VERSION "HNNBNNNYNNNNNNNNNNNNNNNNNNNNNNNNNNNNNNNNNN/4/%%%/4/'%**4NNN///"

NS_ :

BS_:

BU_: LLP_L LLP_R AFS

BO_ 3221225472 VECTOR__INDEPENDENT_SIG_MSG: 0 Vector__XXX
 SG_ New_Signal_167_Copy_17 : 0|1@1+ (1,0) [0|0] "" Vector__XXX
 SG_ New_Signal_167_Copy_16 : 0|1@1+ (1,0) [0|0] "" Vector__XXX
 SG_ New_Signal_167_Copy_15 : 0|1@1+ (1,0) [0|0] "" Vector__XXX
 SG_ New_Signal_167_Copy_14 : 0|1@1+ (1,0) [0|0] "" Vector__XXX
 SG_ SOA_Variante_2 : 0|8@1+ (1,0) [0|255] "" Vector__XXX
 SG_ SOA_Variante : 0|8@1+ (1,0) [0|255] "" Vector__XXX
 SG_ SOA_DimAbLicht_R : 0|8@1+ (0.4,0) [0|100] "Unit_PerCent" Vector__XXX
 SG_ SOA_StGlDim_R : 0|1@1+ (1,0) [0|1] "" Vector__XXX
 SG_ SOA_StGlTest_R : 0|1@1+ (1,0) [0|1] "" Vector__XXX
 SG_ SOA_RefLauf_R : 0|1@1+ (1,0) [0|1] "" Vector__XXX
 SG_ SOA_FehlPos_R : 0|1@1+ (1,0) [0|1] "" Vector__XXX
 SG_ SOA_SollPos_R : 0|12@1+ (0.015625,-31.96875) [-31.96875|31.953125] "Unit_DegreOfArc" Vector__XXX
 SG_ SOA_DimAbLicht_L : 0|8@1+ (0.4,0) [0|100] "Unit_PerCent" Vector__XXX
 SG_ SOA_StGlDim_L : 0|1@1+ (1,0) [0|1] "" Vector__XXX
 SG_ SOA_StGlTest_L : 0|1@1+ (1,0) [0|1] "" Vector__XXX
 SG_ SOA_RefLauf_L : 0|1@1+ (1,0) [0|1] "" Vector__XXX
 SG_ SOA_FehlPos_L : 0|1@1+ (1,0) [0|1] "" Vector__XXX
 SG_ SOA_SollPos_L : 0|12@1+ (0.015625,-31.96875) [-31.96875|31.953125] "Unit_DegreOfArc" Vector__XXX
 SG_ BM_ZV_zu : 0|1@1+ (1,0) [0|1] "" Vector__XXX
 SG_ BM_ZV_auf : 0|1@1+ (1,0) [0|1] "" Vector__XXX
 SG_ BM_Autobahn : 0|1@1+ (1,0) [0|1] "" Vector__XXX
 SG_ LCM_ECE_SAE_Umschaltung_Anf : 0|1@1+ (1,0) [0|1] "" Vector__XXX
 SG_ LCM_Signaturlicht_Anf : 0|1@1+ (1,0) [0|1] "" Vector__XXX
 SG_ LCM_Animiertes_TFL_Anf : 0|3@1+ (1,0) [0|7] "" Vector__XXX
 SG_ LCM_Blinkerwischen_Anf : 0|1@1+ (1,0) [0|1] "" Vector__XXX
 SG_ LCM_Leistungsreduzierung_Anf : 0|2@1+ (1,0) [0|3] "" Vector__XXX
 SG_ LCM_PL_R_Anf : 0|1@1+ (1,0) [0|1] "" Vector__XXX
 SG_ LCM_PL_L_Anf : 0|1@1+ (1,0) [0|1] "" Vector__XXX
 SG_ LCM_PO_R_Anf : 0|1@1+ (1,0) [0|1] "" Vector__XXX
 SG_ LCM_PO_L_Anf : 0|1@1+ (1,0) [0|1] "" Vector__XXX
 SG_ LCM_univ_1_R_Anf : 0|1@1+ (1,0) [0|1] "" Vector__XXX
 SG_ LCM_univ_1_L_Anf : 0|1@1+ (1,0) [0|1] "" Vector__XXX
 SG_ LCM_SM_R_Anf : 0|1@1+ (1,0) [0|1] "" Vector__XXX
 SG_ LCM_SM_L_Anf : 0|1@1+ (1,0) [0|1] "" Vector__XXX
 SG_ LCM_Sh_R_Anf : 0|1@1+ (1,0) [0|1] "" Vector__XXX
 SG_ LCM_Sh_L_Anf : 0|1@1+ (1,0) [0|1] "" Vector__XXX
 SG_ LCM_Blinkerzyklus_R : 0|1@1+ (1,0) [0|1] "" Vector__XXX
 SG_ LCM_Blinkerzyklus_L : 0|1@1+ (1,0) [0|1] "" Vector__XXX
 SG_ LCM_Blinker_R_Anf : 0|1@1+ (1,0) [0|1] "" Vector__XXX
 SG_ LCM_Blinker_L_Anf : 0|1@1+ (1,0) [0|1] "" Vector__XXX
 SG_ LCM_Abschaltung_Vbat_R_Anf : 0|1@1+ (1,0) [0|1] "" Vector__XXX
 SG_ LCM_Abschaltung_Vbat_L_Anf : 0|1@1+ (1,0) [0|1] "" Vector__XXX
 SG_ LCM_TFL_R_Anf : 0|1@1+ (1,0) [0|1] "" Vector__XXX
 SG_ LCM_TFL_L_Anf : 0|1@1+ (1,0) [0|1] "" Vector__XXX
 SG_ LCM_Soll_BZ : 0|4@1+ (1,0) [0|15] "" Vector__XXX
 SG_ LCM_Soll_CRC : 0|8@1+ (1,0) [0|255] "" Vector__XXX
 SG_ LED_L_Abblendl_Anf : 0|1@1+ (1,0) [0|1] "" Vector__XXX
 SG_ LED_L_Abblendl_Schaltart : 0|1@1+ (1,0) [0|1] "" Vector__XXX
 SG_ LED_R_Abblendl_Anf : 0|1@1+ (1,0) [0|1] "" Vector__XXX
 SG_ LED_R_Abblendl_Schaltart : 0|1@1+ (1,0) [0|1] "" Vector__XXX
 SG_ LED_L_Fernl_LH_Anf : 0|1@1+ (1,0) [0|1] "" Vector__XXX
 SG_ LED_L_Fernl_LH_Schaltart : 0|1@1+ (1,0) [0|1] "" Vector__XXX
 SG_ LED_R_Fernl_LH_Anf : 0|1@1+ (1,0) [0|1] "" Vector__XXX
 SG_ LED_R_Fernl_LH_Schaltart : 0|1@1+ (1,0) [0|1] "" Vector__XXX
 SG_ LED_L_Nebel_All_Anf : 0|1@1+ (1,0) [0|1] "" Vector__XXX
 SG_ LED_L_Nebel_All_Schaltart : 0|1@1+ (1,0) [0|1] "" Vector__XXX
 SG_ LED_R_Nebel_All_Anf : 0|1@1+ (1,0) [0|1] "" Vector__XXX
 SG_ LED_R_Nebel_All_Schaltart : 0|1@1+ (1,0) [0|1] "" Vector__XXX
 SG_ LED_Sta_Diag : 0|4@1+ (1,0) [0|15] "" Vector__XXX
 SG_ LED_L_Zus_Fernl_LH_Anf : 0|1@1+ (1,0) [0|1] "" Vector__XXX
 SG_ LED_L_Zus_Fernl_LH_Schaltart : 0|1@1+ (1,0) [0|1] "" Vector__XXX
 SG_ LED_R_Zus_Fernl_LH_Anf : 0|1@1+ (1,0) [0|1] "" Vector__XXX
 SG_ LED_R_Zus_Fernl_LH_Schaltart : 0|1@1+ (1,0) [0|1] "" Vector__XXX
 SG_ SOL_SollPos_L : 0|12@1+ (0.5,-1023) [-1023|1022.5] "Unit_MilliMeter" Vector__XXX
 SG_ SOL_FehlPos_L : 0|1@1+ (1,0) [0|1] "" Vector__XXX
 SG_ SOL_RefLauf_L : 0|1@1+ (1,0) [0|1] "" Vector__XXX
 SG_ SOL_StGlTest_L : 0|1@1+ (1,0) [0|1] "" Vector__XXX
 SG_ SOL_Fehlloesch_L : 0|1@1+ (1,0) [0|1] "" Vector__XXX
 SG_ MO_StartStopp_Motorstopp : 0|1@1+ (1,0) [0|1] "" Vector__XXX
 SG_ MO_StartStopp_Wiederstart : 0|1@1+ (1,0) [0|1] "" Vector__XXX
 SG_ SOL_Tieftemp_Flag : 0|1@1+ (1,0) [0|1] "" Vector__XXX
 SG_ SOL_SollPos_R : 0|12@1+ (0.5,-1023) [-1023|1022.5] "Unit_MilliMeter" Vector__XXX
 SG_ SOL_FehlPos_R : 0|1@1+ (1,0) [0|1] "" Vector__XXX
 SG_ SOL_RefLauf_R : 0|1@1+ (1,0) [0|1] "" Vector__XXX
 SG_ SOL_StGlTest_R : 0|1@1+ (1,0) [0|1] "" Vector__XXX
 SG_ SOL_Fehlloesch_R : 0|1@1+ (1,0) [0|1] "" Vector__XXX
 SG_ SOL_Sta_Diag : 0|4@1+ (1,0) [0|15] "" Vector__XXX
 SG_ MXB_LED_37 : 0|6@1- (1,0) [0|0] "" Vector__XXX
 SG_ MXB_LED_36 : 0|6@1- (1,0) [0|0] "" Vector__XXX
 SG_ MXB_LED_35 : 0|6@1- (1,0) [0|0] "" Vector__XXX
 SG_ MXB_LED_34 : 0|6@1- (1,0) [0|0] "" Vector__XXX
 SG_ MXB_LED_33 : 0|6@1- (1,0) [0|0] "" Vector__XXX
 SG_ MXB_LED_32 : 0|6@1+ (1,0) [0|0] "" Vector__XXX
 SG_ MXB_LED_31 : 0|6@1+ (1,0) [0|0] "" Vector__XXX
 SG_ MXB_LED_30 : 0|6@1+ (1,0) [0|0] "" Vector__XXX
 SG_ MXB_LED_29 : 0|6@1+ (1,0) [0|0] "" Vector__XXX
 SG_ MXB_LED_28 : 0|6@1+ (1,0) [0|0] "" Vector__XXX
 SG_ MXB_LED_27 : 0|6@1+ (1,0) [0|0] "" Vector__XXX
 SG_ MXB_LED_26 : 0|6@1+ (1,0) [0|0] "" Vector__XXX
 SG_ MXB_LED_25 : 0|6@1+ (1,0) [0|0] "" Vector__XXX
 SG_ MXB_LED_24 : 0|6@1+ (1,0) [0|0] "" Vector__XXX
 SG_ MXB_LED_23 : 0|6@1+ (1,0) [0|0] "" Vector__XXX
 SG_ MXB_LED_22 : 0|6@1+ (1,0) [0|0] "" Vector__XXX
 SG_ MXB_LED_21 : 0|6@1+ (1,0) [0|0] "" Vector__XXX
 SG_ MXB_LED_20 : 0|6@1+ (1,0) [0|0] "" Vector__XXX
 SG_ MXB_LED_19 : 0|6@1+ (1,0) [0|0] "" Vector__XXX
 SG_ MXB_LED_18 : 0|6@1+ (1,0) [0|0] "" Vector__XXX
 SG_ MXB_LED_17 : 0|6@1+ (1,0) [0|0] "" Vector__XXX
 SG_ MXB_LED_16 : 0|6@1+ (1,0) [0|0] "" Vector__XXX
 SG_ MXB_LED_15 : 0|6@1+ (1,0) [0|0] "" Vector__XXX
 SG_ MXB_LED_14 : 0|6@1+ (1,0) [0|0] "" Vector__XXX
 SG_ MXB_LED_13 : 0|6@1+ (1,0) [0|0] "" Vector__XXX
 SG_ MXB_LED_12 : 0|6@1+ (1,0) [0|0] "" Vector__XXX
 SG_ MXB_LED_11 : 0|6@1+ (1,0) [0|0] "" Vector__XXX
 SG_ MXB_LED_10 : 0|6@1+ (1,0) [0|0] "" Vector__XXX
 SG_ MXB_LED_09 : 0|6@1+ (1,0) [0|0] "" Vector__XXX
 SG_ MXB_LED_08 : 0|6@1+ (1,0) [0|0] "" Vector__XXX
 SG_ MXB_LED_07 : 0|6@1+ (1,0) [0|0] "" Vector__XXX
 SG_ MXB_LED_06 : 0|6@1+ (1,0) [0|0] "" Vector__XXX
 SG_ MXB_LED_05 : 0|6@1+ (1,0) [0|0] "" Vector__XXX
 SG_ MXB_LED_04 : 0|6@1+ (1,0) [0|0] "" Vector__XXX
 SG_ MXB_LED_03 : 0|6@1+ (1,0) [0|0] "" Vector__XXX
 SG_ MXB_LED_02 : 0|6@1+ (1,0) [0|0] "" Vector__XXX
 SG_ MXB_LED_01 : 0|6@1+ (1,0) [0|0] "" Vector__XXX
 SG_ LED_L_Abbiegel_Anf : 0|1@1+ (1,0) [0|1] "" Vector__XXX
 SG_ LED_L_Abbiegel_Schaltart : 0|1@1+ (1,0) [0|1] "" Vector__XXX
 SG_ LED_R_Abbiegel_Anf : 0|1@1+ (1,0) [0|1] "" Vector__XXX
 SG_ LED_R_Abbiegel_Schaltart : 0|1@1+ (1,0) [0|1] "" Vector__XXX
 SG_ LED_L_Autobahnl_Anf : 0|1@1+ (1,0) [0|1] "" Vector__XXX
 SG_ LED_L_Autobahnl_Schaltart : 0|1@1+ (1,0) [0|1] "" Vector__XXX
 SG_ LED_R_Autobahnl_Anf : 0|1@1+ (1,0) [0|1] "" Vector__XXX
 SG_ LED_R_Autobahnl_Schaltart : 0|1@1+ (1,0) [0|1] "" Vector__XXX
 SG_ LED_L_Eco_Mode_1_Anf : 0|1@1+ (1,0) [0|1] "" Vector__XXX
 SG_ LED_L_Eco_Mode_1_Schaltart : 0|1@1+ (1,0) [0|1] "" Vector__XXX
 SG_ LED_R_Eco_Mode_1_Anf : 0|1@1+ (1,0) [0|1] "" Vector__XXX
 SG_ LED_R_Eco_Mode_1_Schaltart : 0|1@1+ (1,0) [0|1] "" Vector__XXX
 SG_ LED_L_Eco_Mode_2_Anf : 0|1@1+ (1,0) [0|1] "" Vector__XXX
 SG_ LED_L_Eco_Mode_2_Schaltart : 0|1@1+ (1,0) [0|1] "" Vector__XXX
 SG_ LED_R_Eco_Mode_2_Anf : 0|1@1+ (1,0) [0|1] "" Vector__XXX
 SG_ LED_R_Eco_Mode_2_Schaltart : 0|1@1+ (1,0) [0|1] "" Vector__XXX
 SG_ LED_L_Rennl_Anf : 0|1@1+ (1,0) [0|1] "" Vector__XXX
 SG_ LED_L_Rennl_Schaltart : 0|1@1+ (1,0) [0|1] "" Vector__XXX
 SG_ LED_R_Rennl_Anf : 0|1@1+ (1,0) [0|1] "" Vector__XXX
 SG_ LED_R_Rennl_Schaltart : 0|1@1+ (1,0) [0|1] "" Vector__XXX
 SG_ LED_L_Stadtl_Anf : 0|1@1+ (1,0) [0|1] "" Vector__XXX
 SG_ LED_L_Stadtl_Schaltart : 0|1@1+ (1,0) [0|1] "" Vector__XXX
 SG_ LED_R_Stadtl_Anf : 0|1@1+ (1,0) [0|1] "" Vector__XXX
 SG_ LED_R_Stadtl_Schaltart : 0|1@1+ (1,0) [0|1] "" Vector__XXX
 SG_ LED_L_TFL_Anf : 0|2@1+ (1,0) [0|3] "" Vector__XXX
 SG_ LED_L_TFL_Schaltart : 0|1@1+ (1,0) [0|1] "" Vector__XXX
 SG_ LED_R_TFL_Anf : 0|2@1+ (1,0) [0|3] "" Vector__XXX
 SG_ LED_R_TFL_Schaltart : 0|1@1+ (1,0) [0|1] "" Vector__XXX
 SG_ LED_L_Touristenl_Anf : 0|1@1+ (1,0) [0|1] "" Vector__XXX
 SG_ LED_L_Touristenl_Schaltart : 0|1@1+ (1,0) [0|1] "" Vector__XXX
 SG_ LED_R_Touristenl_Anf : 0|1@1+ (1,0) [0|1] "" Vector__XXX
 SG_ LED_R_Touristenl_Schaltart : 0|1@1+ (1,0) [0|1] "" Vector__XXX
 SG_ LED_ECE_SAE_Umschaltung_Anf : 0|1@1+ (1,0) [0|1] "" Vector__XXX
 SG_ LED_Tag_Nacht_Umschaltung_Anf : 0|1@1+ (1,0) [0|1] "" Vector__XXX
 SG_ LED_Sta_Diag : 0|4@1+ (1,0) [0|15] "" Vector__XXX
 SG_ LED_L_Abbiegel_Dimmung : 0|8@1+ (0.4,0) [0|100] "Unit_PerCent" Vector__XXX
 SG_ LED_R_Abbiegel_Dimmung : 0|8@1+ (0.4,0) [0|100] "Unit_PerCent" Vector__XXX

BO_ 351 LED_Soll_Fkt2: 8 Vector__XXX
 SG_ LED_Soll_Fkt2_CRC : 0|8@1+ (1,0) [0|0] "" Vector__XXX
 SG_ LED_Soll_Fkt2_BZ : 8|4@1+ (1,0) [0|0] "" Vector__XXX

BO_ 981 Licht_Anf_01: 8 AFS
 SG_ New_Signal_167_Copy_9 : 12|1@1+ (1,0) [0|0] "" Vector__XXX
 SG_ New_Signal_167_Copy_8 : 13|1@1+ (1,0) [0|0] "" Vector__XXX
 SG_ New_Signal_167_Copy_7 : 14|1@1+ (1,0) [0|0] "" Vector__XXX
 SG_ New_Signal_167_Copy_6 : 16|1@1+ (1,0) [0|0] "" Vector__XXX
 SG_ New_Signal_167_Copy_5 : 17|1@1+ (1,0) [0|0] "" Vector__XXX
 SG_ New_Signal_167_Copy_4 : 18|1@1+ (1,0) [0|0] "" Vector__XXX
 SG_ New_Signal_167_Copy_32 : 19|1@1+ (1,0) [0|0] "" Vector__XXX
 SG_ New_Signal_167_Copy_31 : 20|1@1+ (1,0) [0|0] "" Vector__XXX
 SG_ New_Signal_167_Copy_30 : 21|1@1+ (1,0) [0|0] "" Vector__XXX
 SG_ New_Signal_167_Copy_3 : 22|1@1+ (1,0) [0|0] "" Vector__XXX
 SG_ New_Signal_167_Copy_29 : 23|1@1+ (1,0) [0|0] "" Vector__XXX
 SG_ New_Signal_167_Copy_28 : 24|1@1+ (1,0) [0|0] "" Vector__XXX
 SG_ New_Signal_167_Copy_27 : 25|1@1+ (1,0) [0|0] "" Vector__XXX
 SG_ New_Signal_167_Copy_26 : 26|1@1+ (1,0) [0|0] "" Vector__XXX
 SG_ New_Signal_167_Copy_25 : 27|1@1+ (1,0) [0|0] "" Vector__XXX
 SG_ New_Signal_167_Copy_24 : 28|1@1+ (1,0) [0|0] "" Vector__XXX
 SG_ New_Signal_167_Copy_23 : 29|1@1+ (1,0) [0|0] "" Vector__XXX
 SG_ New_Signal_167_Copy_22 : 30|1@1+ (1,0) [0|0] "" Vector__XXX
 SG_ New_Signal_167_Copy_21 : 31|1@1+ (1,0) [0|0] "" Vector__XXX
 SG_ New_Signal_167_Copy_20 : 32|1@1+ (1,0) [0|0] "" Vector__XXX
 SG_ New_Signal_167_Copy_2 : 33|1@1+ (1,0) [0|0] "" Vector__XXX
 SG_ New_Signal_167_Copy_19 : 34|1@1+ (1,0) [0|0] "" Vector__XXX
 SG_ New_Signal_167_Copy_18 : 35|2@1+ (1,0) [0|0] "" Vector__XXX
 SG_ New_Signal_167_Copy_13 : 40|1@1+ (1,0) [0|0] "" Vector__XXX
 SG_ New_Signal_167_Copy_12 : 41|1@1+ (1,0) [0|0] "" Vector__XXX
 SG_ New_Signal_167_Copy_11 : 42|1@1+ (1,0) [0|0] "" Vector__XXX
 SG_ New_Signal_167_Copy_10 : 43|1@1+ (1,0) [0|0] "" Vector__XXX
 SG_ New_Signal_167_Copy_1 : 44|1@1+ (1,0) [0|0] "" Vector__XXX
 SG_ New_Signal_167 : 45|1@1+ (1,0) [0|0] "" Vector__XXX
 SG_ Licht_Anf_01_CRC : 0|8@1+ (1,0) [0|0] "" Vector__XXX
 SG_ Licht_Anf_01_bz : 8|4@1+ (1,0) [0|0] "" Vector__XXX
 SG_ Licht_Anf_01_Abblendlicht : 15|1@1+ (1,0) [0|0] "" Vector__XXX

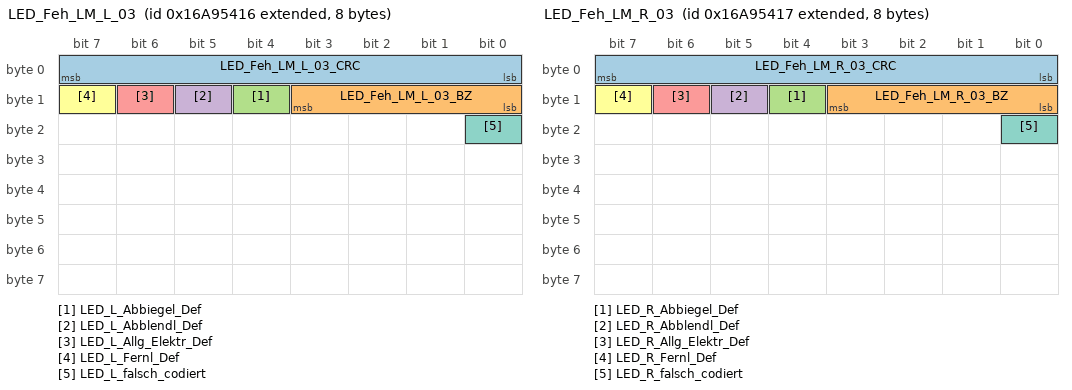
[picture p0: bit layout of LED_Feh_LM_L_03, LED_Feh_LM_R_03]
BO_ 2527679510 LED_Feh_LM_L_03: 8 LLP_L
 SG_ LED_Feh_LM_L_03_CRC : 0|8@1+ (1,0) [0|255] "" Vector__XXX
 SG_ LED_Feh_LM_L_03_BZ : 8|4@1+ (1,0) [0|15] "" Vector__XXX
 SG_ LED_L_Abbiegel_Def : 12|1@1+ (1,0) [0|1] ""  AFS
 SG_ LED_L_Abblendl_Def : 13|1@1+ (1,0) [0|1] ""  AFS
 SG_ LED_L_Allg_Elektr_Def : 14|1@1+ (1,0) [0|1] ""  AFS
 SG_ LED_L_Fernl_Def : 15|1@1+ (1,0) [0|1] ""  AFS
 SG_ LED_L_falsch_codiert : 16|1@1+ (1,0) [0|1] ""  AFS

BO_ 2527679511 LED_Feh_LM_R_03: 8 LLP_R
 SG_ LED_Feh_LM_R_03_CRC : 0|8@1+ (1,0) [0|255] "" Vector__XXX
 SG_ LED_Feh_LM_R_03_BZ : 8|4@1+ (1,0) [0|15] "" Vector__XXX
 SG_ LED_R_Abbiegel_Def : 12|1@1+ (1,0) [0|1] ""  AFS
 SG_ LED_R_Abblendl_Def : 13|1@1+ (1,0) [0|1] ""  AFS
 SG_ LED_R_Allg_Elektr_Def : 14|1@1+ (1,0) [0|1] ""  AFS
 SG_ LED_R_Fernl_Def : 15|1@1+ (1,0) [0|1] ""  AFS
 SG_ LED_R_falsch_codiert : 16|1@1+ (1,0) [0|1] ""  AFS

CM_ "AFSCAN_V1.10F Generated by BUSNET NG Produktiv 9.3.5";
CM_ BU_ LLP_L "LED-Leimo PLUS LINKS";
CM_ BU_ LLP_R "LED-Leimo PLUS RECHTS
";
CM_ BO_ 3221225472 "This is a message for not used signals, created by Vector CANdb++ DBC OLE DB Provider.";
CM_ SG_ 3221225472 SOA_Variante_2 "Dieses Byte erscheint auch im Tester unter der ESG-Ident der Slaves.

Für Fahrzeuge ab S3 (SOP KW48/12) in gemeinsamer Verwendung mit SOA_Variante.

SOA_Variante_2 und SOA_Variante bilden zusammen eine laufende Nummer zur Spezifierung der scheinwerfer";
CM_ SG_ 3221225472 SOA_Variante "Dieses Byte erscheint auch im Tester unter der ESG-Ident der Slaves.

Byte 7 MSB: Scheinwerferlieferant (entspricht der Teilenummer des jeweiligen AFS-Leistungsmoduls)

1111: uncodiert ->(Diese Bitreihenfolge ist für die Slaves zum Senden verboten!)
";
CM_ SG_ 3221225472 SOA_DimAbLicht_R "0 - 100 % bezogen auf die Versorgungsspannung des rechten Moduls";
CM_ SG_ 3221225472 SOA_StGlDim_R "Wert siehe 'Dimmung Abbiegelicht rechts'";
CM_ SG_ 3221225472 SOA_StGlTest_R "(Exakte Position siehe: 'Sollposition Kurvenlicht Schrittmotor Position')";
CM_ SG_ 3221225472 SOA_RefLauf_R "Referenzlauf des rechten Schrittmotors
[erfolgt defaultmäßig beim Motorstart]
(Exakte Position siehe: 'Sollposition Kurvenlicht Schrittmotor Position')";
CM_ SG_ 3221225472 SOA_FehlPos_R "dynamisches Kurvenlicht Fehlerfallposition des rechten Scheinwerfers";
CM_ SG_ 3221225472 SOA_SollPos_R "Sollwert (Schwenkwinkel) des Schrittmotors des dynamischen Kurvenlichtes im rechten Scheinwerfer
(Offset zur Nulllage im linken Scheinwerfer)
Nulllage ist gleich dem Initwert und Fehlerfallposition!
Positives Vorzeichen entspricht Linksschwenken (mathe";
CM_ SG_ 3221225472 SOA_DimAbLicht_L "0 - 100 % bezogen auf die Versorgungsspannung des linken Moduls";
CM_ SG_ 3221225472 SOA_StGlDim_L "Wert siehe 'Dimmung Abbiegelicht links'";
CM_ SG_ 3221225472 SOA_StGlTest_L "(Exakte Position siehe: 'Sollposition Kurvenlicht Schrittmotor Position')";
CM_ SG_ 3221225472 SOA_RefLauf_L "Referenzlauf des linken Schrittmotors
[erfolgt defaultmäßig beim Motorstart]
(Exakte Position siehe: 'Sollposition Kurvenlicht Schrittmotor Position')";
CM_ SG_ 3221225472 SOA_FehlPos_L "dynamisches Kurvenlicht Fehlerfallposition des linken Scheinwerfers";
CM_ SG_ 3221225472 SOA_SollPos_L "Sollwert (Schwenkwinkel) des Schrittmotors des dynamischen Kurvenlichtes im linken Scheinwerfer
(Offset zur Nulllage im linken Scheinwerfer)
Nulllage ist gleich dem Initwert und Fehlerfallposition!
Positives Vorzeichen entspricht Linksschwenken (mathem";
CM_ SG_ 3221225472 BM_ZV_zu "Blinken bei ZV zu

";
CM_ SG_ 3221225472 BM_ZV_auf "Blinken bei ZV auf

";
CM_ SG_ 3221225472 BM_Autobahn "Status Autobahnblinken
";
CM_ SG_ 3221225472 LCM_ECE_SAE_Umschaltung_Anf "Anforderung Umschaltung für LCM";
CM_ SG_ 3221225472 LCM_Signaturlicht_Anf "Ansteuerung Signaturlicht";
CM_ SG_ 3221225472 LCM_Animiertes_TFL_Anf "Anforderung TFL-Animation";
CM_ SG_ 3221225472 LCM_Blinkerwischen_Anf "Anforderung Blinkerwischen";
CM_ SG_ 3221225472 LCM_Leistungsreduzierung_Anf "Anfrage Leistungsreduzierung (BCM1 -->  LCM)";
CM_ SG_ 3221225472 LCM_PL_R_Anf "PL Ansteuerung rechts";
CM_ SG_ 3221225472 LCM_PL_L_Anf "PL Ansteuerung links";
CM_ SG_ 3221225472 LCM_PO_R_Anf "PO Ansteuerung rechts";
CM_ SG_ 3221225472 LCM_PO_L_Anf "PO Ansteuerung links";
CM_ SG_ 3221225472 LCM_univ_1_R_Anf "zusätzlicher High Side Schalter rechts";
CM_ SG_ 3221225472 LCM_univ_1_L_Anf "zusätzlicher High Side Schalter links";
CM_ SG_ 3221225472 LCM_SM_R_Anf "Sidemarker Ansteuerung rechts";
CM_ SG_ 3221225472 LCM_SM_L_Anf "Sidemarker Ansteuerung links";
CM_ SG_ 3221225472 LCM_Sh_R_Anf "Shutter Ansteuerung rechts";
CM_ SG_ 3221225472 LCM_Sh_L_Anf "Shutter Ansteuerung links";
CM_ SG_ 3221225472 LCM_Blinkerzyklus_R "Blinkfunktion/zyklus rechts (in)aktiv";
CM_ SG_ 3221225472 LCM_Blinkerzyklus_L "Blinkfunktion/zyklus links (in)aktiv";
CM_ SG_ 3221225472 LCM_Blinker_R_Anf "Blinker Ansteuerung rechts (inkl.Takt)";
CM_ SG_ 3221225472 LCM_Blinker_L_Anf "Blinker Ansteuerung links (inkl.Takt)";
CM_ SG_ 3221225472 LCM_Abschaltung_Vbat_R_Anf "Anfrage Abschaltung Vbat LCM rechts";
CM_ SG_ 3221225472 LCM_Abschaltung_Vbat_L_Anf "Anfrage Abschaltung Vbat LCM links";
CM_ SG_ 3221225472 LCM_TFL_R_Anf "TFL Ansteuerung rechts";
CM_ SG_ 3221225472 LCM_TFL_L_Anf "TFL Ansteuerung links";
CM_ SG_ 3221225472 LCM_Soll_BZ "Botschaftszaehler";
CM_ SG_ 3221225472 LCM_Soll_CRC "Checksumme nach CRC8 Algo";
CM_ SG_ 3221225472 LED_L_Abblendl_Anf "Abblendlicht-Anforderung";
CM_ SG_ 3221225472 LED_L_Abblendl_Schaltart "Signal entscheidet, ob Abblendlicht gedimmt oder unmittelbar ein- bzw. ausgeschaltet wird
(Eine eventuelle Dimmung ist im LED-LM abzulegen)";
CM_ SG_ 3221225472 LED_R_Abblendl_Anf "Abblendlicht-Anforderung";
CM_ SG_ 3221225472 LED_R_Abblendl_Schaltart "Signal entscheidet, ob Abblendlicht gedimmt oder unmittelbar ein- bzw. ausgeschaltet wird
(Eine eventuelle Dimmung ist im LED-LM abzulegen)";
CM_ SG_ 3221225472 LED_L_Fernl_LH_Schaltart "Signal entscheidet, ob Fernlicht gedimmt oder unmittelbar ein- bzw. ausgeschaltet wird (Eine eventuelle Dimmung ist im LED-LM abzulegen)";
CM_ SG_ 3221225472 LED_R_Fernl_LH_Schaltart "Signal entscheidet, ob Fernlicht gedimmt oder unmittelbar ein- bzw. ausgeschaltet wird (Eine eventuelle Dimmung ist im LED-LM abzulegen)";
CM_ SG_ 3221225472 LED_Sta_Diag "1010: Normalbetrieb: Diagnose nicht eingeleitet. Eine Umcodierung, Stellgliedtest, und Fehlerspeicherlöschen der Slaves ist über diese Bitreihenfolge verriegelt!
0101: Diagnosebetrieb. Diagnose mit VAS Tester läuft. Ein Stellgliedtest, und Fehlerspeicher1010: Normalbetrieb: Diagnose nicht eingeleitet. Eine Umcodierung, Stellgliedtest, und Fehlerspeicherlöschen der Slaves ist über diese Bitreihenfolge verriegelt!
0101: Diagnosebetrieb. Diagnose mit VAS Tester läuft. Ein Stellgliedtest, und Fehlerspeicher";
CM_ SG_ 3221225472 LED_L_Zus_Fernl_LH_Anf "Anforderung LED Zusatzfernlicht links ";
CM_ SG_ 3221225472 LED_L_Zus_Fernl_LH_Schaltart "Signal entscheidet, ob Fernlicht gedimmt oder unmittelbar ein- bzw. ausgeschaltet wird (Eine eventuelle Dimmung ist im LED-LM abzulegen)";
CM_ SG_ 3221225472 LED_R_Zus_Fernl_LH_Anf "Anforderung LED Zusatzfernlicht rechts";
CM_ SG_ 3221225472 LED_R_Zus_Fernl_LH_Schaltart "Signal entscheidet, ob Fernlicht gedimmt oder unmittelbar ein- bzw. ausgeschaltet wird (Eine eventuelle Dimmung ist im LED-LM abzulegen)";
CM_ SG_ 3221225472 SOL_SollPos_L "Sollneigung in [mm] des linken Abblendlichtbündels in 10 m Entfernung bezogen auf die Grundeinstellung des Abblendlichtes (-1,0% Neigung am leeren Fahrzeug)
z.B. 0 mm heißt -1,0% Neigung des Abblendlichtbündels (Änderung des Wertebereichs)
negatives Vor";
CM_ SG_ 3221225472 SOL_FehlPos_L "LWR Fehlerfallposition des linken Schrittmotors
Fehlerposition bei 'Bus Off' -200 mm";
CM_ SG_ 3221225472 SOL_RefLauf_L "Referenzlauf des linken Schrittmotors
[erfolgt defaultmäßig beim Motorstart]
(Exakte Position siehe: 'Sollposition LWR Schrittmotor')";
CM_ SG_ 3221225472 SOL_StGlTest_L "(Exakte Position siehe: 'Sollposition LWR Schrittmotor')";
CM_ SG_ 3221225472 SOL_Fehlloesch_L "Aufforderung zum Fehlerspeicher löschen im linken AFS Elektronik Modul!";
CM_ SG_ 3221225472 MO_StartStopp_Motorstopp "Motor-Stopp durch Start/Stopp-Koordinator
HYBRID:
Wenn MO_Hybridfahrzeug = 1 gilt:
Verbrennungsmotor durch Hybrid-Koordinator im MSG ausgeschaltet. 
Die definierten Start/Stopp-Signale beziehen sich nur auf den Verbrennungsmotor!";
CM_ SG_ 3221225472 MO_StartStopp_Wiederstart "Motorwiederstart durch Start/Stopp-Koordinator
HYBRID:
Wenn MO_Hybridfahrzeug =1 gilt:
Warnung vor Spannungseinbruch beim Zustart des Verbrennungsmotors. 
-nicht relevant, da derzeit kein Start über 12V-Starter geplant-
Dieses Signal wird nur vom Hyb";
CM_ SG_ 3221225472 SOL_Tieftemp_Flag "Dieses Bit wird bei einer über das Bordnetz gemessenen Außentemperatur kleiner als -30°C auf den Wert '1' gesetzt";
CM_ SG_ 3221225472 SOL_SollPos_R "Sollneigung in [mm] des rechten Abblendlichtbündels in 10 m Entfernung bezogen auf die Grundeinstellung des Abblendlichtes (-1,0% Neigung am leeren Fahrzeug)
z.B. 0 mm heißt -1,0% Neigung des Abblendlichtbündels (Änderung des Wertebereichs)
negatives Vo";
CM_ SG_ 3221225472 SOL_FehlPos_R "LWR Fehlerfallposition des rechten Schrittmotors";
CM_ SG_ 3221225472 SOL_RefLauf_R "Referenzlauf des rechten Schrittmotors
[erfolgt defaultmäßig beim Motorstart]
(Exakte Position siehe: 'Sollposition LWR Schrittmotor')";
CM_ SG_ 3221225472 SOL_StGlTest_R "(Exakte Position siehe: 'Sollposition LWR Schrittmotor')";
CM_ SG_ 3221225472 SOL_Fehlloesch_R "Aufforderung zum Fehlerspeicher löschen im rechten AFS Elektronik Modul!";
CM_ SG_ 3221225472 SOL_Sta_Diag "1010: Normalbetrieb: Diagnose nicht eingeleitet. Eine Umcodierung, Stellgliedtest, und Fehlerspeicherlöschen der Slaves ist über diese Bitreihenfolge verriegelt!
0101: Diagnosebetrieb. Diagnose mit VAS Tester läuft. Ein Stellgliedtest, und Fehlerspeicher";
CM_ SG_ 3221225472 LED_L_Eco_Mode_1_Anf "Anforderung Eco-Mode, d. h. einer gedimmten Ansteuerung des Abblendlichtes (anhand im LED_LM_L/R hinterlegter Dimmwerte)";
CM_ SG_ 3221225472 LED_L_Eco_Mode_1_Schaltart "LED_LM_L (Abblendlicht), LED_LM_R (Abblendlicht)";
CM_ SG_ 3221225472 LED_R_Eco_Mode_1_Anf "Anforderung Eco-Mode, d. h. einer gedimmten Ansteuerung des Abblendlichtes (anhand im LED_LM_L/R hinterlegter Dimmwerte)";
CM_ SG_ 3221225472 LED_R_Eco_Mode_1_Schaltart "LED_LM_L (Abblendlicht), LED_LM_R (Abblendlicht)";
CM_ SG_ 3221225472 LED_L_Eco_Mode_2_Anf "Anforderung Eco-Mode, d. h. einer gedimmten Ansteuerung des Abblendlichtes (anhand im LED_LM_L/R hinterlegter Dimmwerte)";
CM_ SG_ 3221225472 LED_L_Eco_Mode_2_Schaltart "LED_LM_L (Abblendlicht), LED_LM_R (Abblendlicht)";
CM_ SG_ 3221225472 LED_R_Eco_Mode_2_Anf "Anforderung Eco-Mode, d. h. einer gedimmten Ansteuerung des Abblendlichtes (anhand im LED_LM_L/R hinterlegter Dimmwerte)";
CM_ SG_ 3221225472 LED_R_Eco_Mode_2_Schaltart "LED_LM_L (Abblendlicht), LED_LM_R (Abblendlicht)";
CM_ SG_ 3221225472 LED_L_TFL_Schaltart "LED_LM_L (Abblendlicht), LED_LM_R (Abblendlicht)";
CM_ SG_ 3221225472 LED_R_TFL_Schaltart "LED_LM_L (Abblendlicht), LED_LM_R (Abblendlicht)";
CM_ SG_ 3221225472 LED_L_Touristenl_Schaltart "Signal entscheidet, ob Touristenlicht gedimmt oder unmittelbar ein- bzw. ausgeschaltet wird
(Eine eventuelle Dimmung ist im LED-LM abzulegen)";
CM_ SG_ 3221225472 LED_R_Touristenl_Schaltart "Signal entscheidet, ob Touristenlicht gedimmt oder unmittelbar ein- bzw. ausgeschaltet wird
(Eine eventuelle Dimmung ist im LED-LM abzulegen)";
CM_ SG_ 3221225472 LED_Tag_Nacht_Umschaltung_Anf "Anforderung Tag/Nacht-Umschaltung";
CM_ SG_ 3221225472 LED_L_Abbiegel_Dimmung "Dimmung des linken Abbiegelichtes in %PWM, bezogen auf die Versorgungsspannung";
CM_ SG_ 3221225472 LED_R_Abbiegel_Dimmung "Dimmung des rechten Abbiegelichtes in %PWM, bezogen auf die Versorgungsspannung";
CM_ SG_ 2527679510 LED_Feh_LM_L_03_CRC "Checksumme für LED_Feh_LM_L_03-Botschaft";
CM_ SG_ 2527679510 LED_Feh_LM_L_03_BZ "Botschaftszähler für LED_Feh_LM_L_03-Botschaft";
CM_ SG_ 2527679510 LED_L_Abbiegel_Def "Abbiegelichtfehler";
CM_ SG_ 2527679510 LED_L_Abblendl_Def "Fehler Abblendlicht";
CM_ SG_ 2527679510 LED_L_Allg_Elektr_Def "LED-Leimo defekt";
CM_ SG_ 2527679510 LED_L_Fernl_Def "Fernlichtfehler";
CM_ SG_ 2527679510 LED_L_falsch_codiert "LED-Leimo-Codierung entspricht nicht der Vorgabe durch das Master-SG";
CM_ SG_ 2527679511 LED_Feh_LM_R_03_CRC "Checksumme für LED_Feh_LM_L_03-Botschaft";
CM_ SG_ 2527679511 LED_Feh_LM_R_03_BZ "Botschaftszähler für LED_Feh_LM_R_03-Botschaft";
CM_ SG_ 2527679511 LED_R_Abbiegel_Def "Abbiegelichtfehler";
CM_ SG_ 2527679511 LED_R_Abblendl_Def "Fehler Abblendlicht";
CM_ SG_ 2527679511 LED_R_Allg_Elektr_Def "LED-Leimo defekt";
CM_ SG_ 2527679511 LED_R_Fernl_Def "Fernlichtfehler";
CM_ SG_ 2527679511 LED_R_falsch_codiert "LED-Leimo-Codierung entspricht nicht der Vorgabe durch das Master-SG";
BA_DEF_  "DBName" STRING ;
BA_DEF_  "GenNWMApBusSleep" STRING ;
BA_DEF_  "GenNWMApCanNormal" STRING ;
BA_DEF_  "GenNWMApCanOff" STRING ;
BA_DEF_  "GenNWMApCanOn" STRING ;
BA_DEF_  "GenNWMApCanSleep" STRING ;
BA_DEF_  "GenNWMApCanWakeUp" STRING ;
BA_DEF_  "GenNWMGotoMode_Awake" STRING ;
BA_DEF_  "GenNWMGotoMode_BusSleep" STRING ;
BA_DEF_  "GenNWMSleepTime" INT 0 1000000;
BA_DEF_  "GenNWMTalkNM" STRING ;
BA_DEF_  "Manufacturer" STRING ;
BA_DEF_  "NmType" STRING ;
BA_DEF_  "VAGTP20_SetupMessageCount" INT 0 255;
BA_DEF_  "VAGTP20_SetupStartAddress" HEX 0 2047;
BA_DEF_  "VersionDay" INT 1 31;
BA_DEF_  "VersionMonth" INT 1 12;
BA_DEF_  "VersionWeek" INT 1 52;
BA_DEF_  "VersionYear" INT 0 99;
BA_DEF_  "VersionNumber" INT 0 65535;
BA_DEF_  "Baudrate" INT 0 1000000;
BA_DEF_  "SamplePointMin" INT 1 100;
BA_DEF_  "SamplePointMax" INT 1 100;
BA_DEF_  "SyncJumpWidthMin" INT 1 4;
BA_DEF_  "SyncJumpWidthMax" INT 1 4;
BA_DEF_ BU_  "GenNodAutoGenDsp" ENUM  "No","Yes";
BA_DEF_ BU_  "GenNodAutoGenSnd" ENUM  "No","Yes";
BA_DEF_ BU_  "GenNodSleepTime" INT 0 1000000;
BA_DEF_ BU_  "ILUsed" ENUM  "No","Yes";
BA_DEF_ BU_  "ECUVariantDefault" ENUM  "No","Yes";
BA_DEF_ BU_  "NodeLayerModules" STRING ;
BA_DEF_ BU_  "NmhNode" ENUM  "No","Yes";
BA_DEF_ BU_  "NmNode" ENUM  "No","Yes";
BA_DEF_ BO_  "DiagRequest" ENUM  "No","Yes";
BA_DEF_ BO_  "DiagResponse" ENUM  "No","Yes";
BA_DEF_ BO_  "DiagState" ENUM  "No","Yes";
BA_DEF_ BO_  "GenMsgCycleTime" INT 0 65535;
BA_DEF_ BO_  "GenMsgILSupport" ENUM  "No","Yes";
BA_DEF_ BO_  "GenMsgSendType" ENUM  "Cyclic","not_used","not_used","not_used","not_used","not_used","not_used","IfActive","NoMsgSendType";
BA_DEF_ BO_  "GenMsgStartDelayTime" INT 0 100000;
BA_DEF_ BO_  "NmMessage" ENUM  "No","Yes";
BA_DEF_ BO_  "NmhMessage" ENUM  "No","Yes";
BA_DEF_ BO_  "MsgType" ENUM  "Application","NM ","NMH","TP2.0","ISO-TP ","BAP","EID","KS";
BA_DEF_ BO_  "VAGTP20_API" HEX 0 255;
BA_DEF_ BO_  "VAGTP20_DynConnection" ENUM  "No","Yes";
BA_DEF_ BO_  "VAGTP20_DynSetup" ENUM  "No","Yes";
BA_DEF_ BO_  "VAGTP20_StatConnection" ENUM  "No","Yes";
BA_DEF_ SG_  "GenSigActiveRepetitions" INT -2147483648 2147483647;
BA_DEF_ SG_  "GenSigSendType" ENUM  "Cyclic","OnWrite","OnWriteWithRepetition","OnChange","OnChangeWithRepetition","IfActive","IfActiveWithRepetition","NoSigSendType","OnChangeAndIfActive","OnChangeAndIfActiveWithRepetition";
BA_DEF_ SG_  "GenSigStartValue" INT -2147483648 2147483647;
BA_DEF_ SG_  "NWM-WakeupAllowed" ENUM  "No","Yes";
BA_DEF_ SG_  "GenSigFuncType" ENUM  "NoFunction","MsgCounter","CRC-8","XOR","XOR-2","DatedBit","SW-Kl15","CHK","Constant","Protocol","CRC-8-SAE_J1850";
BA_DEF_ SG_  "GenSigSwitchedByIgnition" ENUM  "No","Yes";
BA_DEF_ SG_  "Fehlerwert" HEX 0 2147483647;
BA_DEF_ SG_  "GenSigMissingSourceValue" HEX 0 2147483647;
BA_DEF_REL_ BU_SG_REL_  "GenSigTimeoutTime" INT 0 65535;
BA_DEF_DEF_  "DBName" "";
BA_DEF_DEF_  "GenNWMApBusSleep" "";
BA_DEF_DEF_  "GenNWMApCanNormal" "";
BA_DEF_DEF_  "GenNWMApCanOff" "";
BA_DEF_DEF_  "GenNWMApCanOn" "";
BA_DEF_DEF_  "GenNWMApCanSleep" "";
BA_DEF_DEF_  "GenNWMApCanWakeUp" "";
BA_DEF_DEF_  "GenNWMGotoMode_Awake" "";
BA_DEF_DEF_  "GenNWMGotoMode_BusSleep" "";
BA_DEF_DEF_  "GenNWMSleepTime" 0;
BA_DEF_DEF_  "GenNWMTalkNM" "";
BA_DEF_DEF_  "Manufacturer" "";
BA_DEF_DEF_  "NmType" "None";
BA_DEF_DEF_  "VAGTP20_SetupMessageCount" 0;
BA_DEF_DEF_  "VAGTP20_SetupStartAddress" 0;
BA_DEF_DEF_  "VersionDay" 4;
BA_DEF_DEF_  "VersionMonth" 11;
BA_DEF_DEF_  "VersionWeek" 45;
BA_DEF_DEF_  "VersionYear" 14;
BA_DEF_DEF_  "VersionNumber" 0;
BA_DEF_DEF_  "Baudrate" 0;
BA_DEF_DEF_  "SamplePointMin" 1;
BA_DEF_DEF_  "SamplePointMax" 1;
BA_DEF_DEF_  "SyncJumpWidthMin" 1;
BA_DEF_DEF_  "SyncJumpWidthMax" 1;
BA_DEF_DEF_  "GenNodAutoGenDsp" "Yes";
BA_DEF_DEF_  "GenNodAutoGenSnd" "Yes";
BA_DEF_DEF_  "GenNodSleepTime" 0;
BA_DEF_DEF_  "ILUsed" "Yes";
BA_DEF_DEF_  "ECUVariantDefault" "Yes";
BA_DEF_DEF_  "NodeLayerModules" "";
BA_DEF_DEF_  "NmhNode" "Yes";
BA_DEF_DEF_  "NmNode" "No";
BA_DEF_DEF_  "DiagRequest" "No";
BA_DEF_DEF_  "DiagResponse" "No";
BA_DEF_DEF_  "DiagState" "No";
BA_DEF_DEF_  "GenMsgCycleTime" 0;
BA_DEF_DEF_  "GenMsgILSupport" "No";
BA_DEF_DEF_  "GenMsgSendType" "NoMsgSendType";
BA_DEF_DEF_  "GenMsgStartDelayTime" 0;
BA_DEF_DEF_  "NmMessage" "No";
BA_DEF_DEF_  "NmhMessage" "No";
BA_DEF_DEF_  "MsgType" "Application";
BA_DEF_DEF_  "VAGTP20_API" 0;
BA_DEF_DEF_  "VAGTP20_DynConnection" "No";
BA_DEF_DEF_  "VAGTP20_DynSetup" "No";
BA_DEF_DEF_  "VAGTP20_StatConnection" "No";
BA_DEF_DEF_  "GenSigActiveRepetitions" 0;
BA_DEF_DEF_  "GenSigSendType" "NoSigSendType";
BA_DEF_DEF_  "GenSigStartValue" 0;
BA_DEF_DEF_  "NWM-WakeupAllowed" "No";
BA_DEF_DEF_  "GenSigFuncType" "NoFunction";
BA_DEF_DEF_  "GenSigSwitchedByIgnition" "Yes";
BA_DEF_DEF_  "Fehlerwert" 0;
BA_DEF_DEF_  "GenSigMissingSourceValue" 0;
BA_DEF_DEF_REL_ "GenSigTimeoutTime" 0;
BA_ "SyncJumpWidthMax" 4;
BA_ "SyncJumpWidthMin" 2;
BA_ "SamplePointMax" 84;
BA_ "SamplePointMin" 80;
BA_ "Baudrate" 500000;
BA_ "VersionNumber" 10;
BA_ "VAGTP20_SetupStartAddress" 512;
BA_ "VAGTP20_SetupMessageCount" 128;
BA_ "Manufacturer" "VAG";
BA_ "GenNWMSleepTime" 4000;
BA_ "DBName" "AFSCAN";
BA_ "GenNodSleepTime" BU_ LLP_L 4000;
BA_ "GenNodSleepTime" BU_ LLP_R 4000;
BA_ "NmhNode" BU_ AFS 0;
BA_ "GenNodSleepTime" BU_ AFS 4000;
BA_ "GenMsgCycleTime" BO_ 351 200;
BA_ "GenMsgCycleTime" BO_ 981 100;
BA_ "GenMsgSendType" BO_ 2527679510 0;
BA_ "GenMsgILSupport" BO_ 2527679510 1;
BA_ "GenMsgCycleTime" BO_ 2527679510 200;
BA_ "GenMsgSendType" BO_ 2527679511 0;
BA_ "GenMsgILSupport" BO_ 2527679511 1;
BA_ "GenMsgCycleTime" BO_ 2527679511 200;
BA_ "GenSigSendType" SG_ 3221225472 SOA_Variante_2 0;
BA_ "GenSigSendType" SG_ 3221225472 SOA_Variante 0;
BA_ "GenSigSendType" SG_ 3221225472 SOA_DimAbLicht_R 0;
BA_ "Fehlerwert" SG_ 3221225472 SOA_DimAbLicht_R 255;
BA_ "GenSigSendType" SG_ 3221225472 SOA_StGlDim_R 0;
BA_ "GenSigSendType" SG_ 3221225472 SOA_StGlTest_R 0;
BA_ "GenSigSendType" SG_ 3221225472 SOA_RefLauf_R 0;
BA_ "GenSigSendType" SG_ 3221225472 SOA_FehlPos_R 0;
BA_ "GenSigSendType" SG_ 3221225472 SOA_SollPos_R 0;
BA_ "GenSigStartValue" SG_ 3221225472 SOA_SollPos_R 4094;
BA_ "Fehlerwert" SG_ 3221225472 SOA_SollPos_R 4095;
BA_ "GenSigSendType" SG_ 3221225472 SOA_DimAbLicht_L 0;
BA_ "Fehlerwert" SG_ 3221225472 SOA_DimAbLicht_L 255;
BA_ "GenSigSendType" SG_ 3221225472 SOA_StGlDim_L 0;
BA_ "GenSigSendType" SG_ 3221225472 SOA_StGlTest_L 0;
BA_ "GenSigSendType" SG_ 3221225472 SOA_RefLauf_L 0;
BA_ "GenSigSendType" SG_ 3221225472 SOA_FehlPos_L 0;
BA_ "GenSigSendType" SG_ 3221225472 SOA_SollPos_L 0;
BA_ "GenSigStartValue" SG_ 3221225472 SOA_SollPos_L 4094;
BA_ "Fehlerwert" SG_ 3221225472 SOA_SollPos_L 4095;
BA_ "GenSigSendType" SG_ 3221225472 BM_ZV_zu 3;
BA_ "GenSigSendType" SG_ 3221225472 BM_ZV_auf 3;
BA_ "GenSigSendType" SG_ 3221225472 BM_Autobahn 3;
BA_ "GenSigSendType" SG_ 3221225472 LCM_ECE_SAE_Umschaltung_Anf 0;
BA_ "GenSigSendType" SG_ 3221225472 LCM_Signaturlicht_Anf 3;
BA_ "GenSigSendType" SG_ 3221225472 LCM_Animiertes_TFL_Anf 3;
BA_ "GenSigSendType" SG_ 3221225472 LCM_Blinkerwischen_Anf 3;
BA_ "GenSigSendType" SG_ 3221225472 LCM_Leistungsreduzierung_Anf 3;
BA_ "GenSigSendType" SG_ 3221225472 LCM_PL_R_Anf 3;
BA_ "GenSigSendType" SG_ 3221225472 LCM_PL_L_Anf 3;
BA_ "GenSigSendType" SG_ 3221225472 LCM_PO_R_Anf 3;
BA_ "GenSigSendType" SG_ 3221225472 LCM_PO_L_Anf 3;
BA_ "GenSigSendType" SG_ 3221225472 LCM_univ_1_R_Anf 3;
BA_ "GenSigSendType" SG_ 3221225472 LCM_univ_1_L_Anf 3;
BA_ "GenSigSendType" SG_ 3221225472 LCM_SM_R_Anf 3;
BA_ "GenSigSendType" SG_ 3221225472 LCM_SM_L_Anf 3;
BA_ "GenSigSendType" SG_ 3221225472 LCM_Sh_R_Anf 3;
BA_ "GenSigSendType" SG_ 3221225472 LCM_Sh_L_Anf 3;
BA_ "GenSigSendType" SG_ 3221225472 LCM_Blinkerzyklus_R 3;
BA_ "GenSigSendType" SG_ 3221225472 LCM_Blinkerzyklus_L 3;
BA_ "GenSigSendType" SG_ 3221225472 LCM_Blinker_R_Anf 3;
BA_ "GenSigSendType" SG_ 3221225472 LCM_Blinker_L_Anf 3;
BA_ "GenSigSendType" SG_ 3221225472 LCM_Abschaltung_Vbat_R_Anf 3;
BA_ "GenSigSendType" SG_ 3221225472 LCM_Abschaltung_Vbat_L_Anf 3;
BA_ "GenSigSendType" SG_ 3221225472 LCM_TFL_R_Anf 3;
BA_ "GenSigSendType" SG_ 3221225472 LCM_TFL_L_Anf 3;
BA_ "GenSigSendType" SG_ 3221225472 LCM_Soll_BZ 0;
BA_ "GenSigFuncType" SG_ 3221225472 LCM_Soll_BZ 1;
BA_ "GenSigSendType" SG_ 3221225472 LCM_Soll_CRC 0;
BA_ "GenSigFuncType" SG_ 3221225472 LCM_Soll_CRC 2;
BA_ "GenSigSendType" SG_ 3221225472 LED_L_Abblendl_Anf 0;
BA_ "GenSigSendType" SG_ 3221225472 LED_L_Abblendl_Schaltart 0;
BA_ "GenSigSendType" SG_ 3221225472 LED_R_Abblendl_Anf 0;
BA_ "GenSigSendType" SG_ 3221225472 LED_R_Abblendl_Schaltart 0;
BA_ "GenSigSendType" SG_ 3221225472 LED_L_Fernl_LH_Anf 0;
BA_ "GenSigSendType" SG_ 3221225472 LED_L_Fernl_LH_Schaltart 0;
BA_ "GenSigSendType" SG_ 3221225472 LED_R_Fernl_LH_Anf 0;
BA_ "GenSigSendType" SG_ 3221225472 LED_R_Fernl_LH_Schaltart 0;
BA_ "GenSigSendType" SG_ 3221225472 LED_L_Nebel_All_Anf 0;
BA_ "GenSigSendType" SG_ 3221225472 LED_L_Nebel_All_Schaltart 0;
BA_ "GenSigSendType" SG_ 3221225472 LED_R_Nebel_All_Anf 0;
BA_ "GenSigSendType" SG_ 3221225472 LED_R_Nebel_All_Schaltart 0;
BA_ "GenSigSendType" SG_ 3221225472 LED_Sta_Diag 0;
BA_ "GenSigSendType" SG_ 3221225472 LED_L_Zus_Fernl_LH_Anf 0;
BA_ "GenSigSendType" SG_ 3221225472 LED_L_Zus_Fernl_LH_Schaltart 0;
BA_ "GenSigSendType" SG_ 3221225472 LED_R_Zus_Fernl_LH_Anf 0;
BA_ "GenSigSendType" SG_ 3221225472 LED_R_Zus_Fernl_LH_Schaltart 0;
BA_ "Fehlerwert" SG_ 3221225472 SOL_SollPos_L 4095;
BA_ "GenSigStartValue" SG_ 3221225472 SOL_SollPos_L 4094;
BA_ "GenSigSendType" SG_ 3221225472 SOL_SollPos_L 0;
BA_ "GenSigSendType" SG_ 3221225472 SOL_FehlPos_L 0;
BA_ "GenSigSendType" SG_ 3221225472 SOL_RefLauf_L 0;
BA_ "GenSigSendType" SG_ 3221225472 SOL_StGlTest_L 0;
BA_ "GenSigSendType" SG_ 3221225472 SOL_Fehlloesch_L 0;
BA_ "GenSigSendType" SG_ 3221225472 MO_StartStopp_Motorstopp 0;
BA_ "GenSigSendType" SG_ 3221225472 MO_StartStopp_Wiederstart 0;
BA_ "GenSigSendType" SG_ 3221225472 SOL_Tieftemp_Flag 0;
BA_ "Fehlerwert" SG_ 3221225472 SOL_SollPos_R 4095;
BA_ "GenSigStartValue" SG_ 3221225472 SOL_SollPos_R 4094;
BA_ "GenSigSendType" SG_ 3221225472 SOL_SollPos_R 0;
BA_ "GenSigSendType" SG_ 3221225472 SOL_FehlPos_R 0;
BA_ "GenSigSendType" SG_ 3221225472 SOL_RefLauf_R 0;
BA_ "GenSigSendType" SG_ 3221225472 SOL_StGlTest_R 0;
BA_ "GenSigSendType" SG_ 3221225472 SOL_Fehlloesch_R 0;
BA_ "GenSigSendType" SG_ 3221225472 SOL_Sta_Diag 0;
BA_ "GenSigSendType" SG_ 3221225472 LED_L_Abbiegel_Anf 0;
BA_ "GenSigSendType" SG_ 3221225472 LED_L_Abbiegel_Schaltart 0;
BA_ "GenSigSendType" SG_ 3221225472 LED_R_Abbiegel_Anf 0;
BA_ "GenSigSendType" SG_ 3221225472 LED_R_Abbiegel_Schaltart 0;
BA_ "GenSigSendType" SG_ 3221225472 LED_L_Autobahnl_Anf 0;
BA_ "GenSigSendType" SG_ 3221225472 LED_L_Autobahnl_Schaltart 0;
BA_ "GenSigSendType" SG_ 3221225472 LED_R_Autobahnl_Anf 0;
BA_ "GenSigSendType" SG_ 3221225472 LED_R_Autobahnl_Schaltart 0;
BA_ "GenSigSendType" SG_ 3221225472 LED_L_Eco_Mode_1_Anf 0;
BA_ "GenSigSendType" SG_ 3221225472 LED_L_Eco_Mode_1_Schaltart 0;
BA_ "GenSigSendType" SG_ 3221225472 LED_R_Eco_Mode_1_Anf 0;
BA_ "GenSigSendType" SG_ 3221225472 LED_R_Eco_Mode_1_Schaltart 0;
BA_ "GenSigSendType" SG_ 3221225472 LED_L_Eco_Mode_2_Anf 0;
BA_ "GenSigSendType" SG_ 3221225472 LED_L_Eco_Mode_2_Schaltart 0;
BA_ "GenSigSendType" SG_ 3221225472 LED_R_Eco_Mode_2_Anf 0;
BA_ "GenSigSendType" SG_ 3221225472 LED_R_Eco_Mode_2_Schaltart 0;
BA_ "GenSigSendType" SG_ 3221225472 LED_L_Rennl_Anf 0;
BA_ "GenSigSendType" SG_ 3221225472 LED_L_Rennl_Schaltart 0;
BA_ "GenSigSendType" SG_ 3221225472 LED_R_Rennl_Anf 0;
BA_ "GenSigSendType" SG_ 3221225472 LED_R_Rennl_Schaltart 0;
BA_ "GenSigSendType" SG_ 3221225472 LED_L_Stadtl_Anf 0;
BA_ "GenSigSendType" SG_ 3221225472 LED_L_Stadtl_Schaltart 0;
BA_ "GenSigSendType" SG_ 3221225472 LED_R_Stadtl_Anf 0;
BA_ "GenSigSendType" SG_ 3221225472 LED_R_Stadtl_Schaltart 0;
BA_ "GenSigSendType" SG_ 3221225472 LED_L_TFL_Anf 0;
BA_ "GenSigSendType" SG_ 3221225472 LED_L_TFL_Schaltart 0;
BA_ "GenSigSendType" SG_ 3221225472 LED_R_TFL_Anf 0;
BA_ "GenSigSendType" SG_ 3221225472 LED_R_TFL_Schaltart 0;
BA_ "GenSigSendType" SG_ 3221225472 LED_L_Touristenl_Anf 0;
BA_ "GenSigSendType" SG_ 3221225472 LED_L_Touristenl_Schaltart 0;
BA_ "GenSigSendType" SG_ 3221225472 LED_R_Touristenl_Anf 0;
BA_ "GenSigSendType" SG_ 3221225472 LED_R_Touristenl_Schaltart 0;
BA_ "GenSigSendType" SG_ 3221225472 LED_ECE_SAE_Umschaltung_Anf 0;
BA_ "GenSigSendType" SG_ 3221225472 LED_Tag_Nacht_Umschaltung_Anf 0;
BA_ "Fehlerwert" SG_ 3221225472 LED_L_Abbiegel_Dimmung 255;
BA_ "GenSigSendType" SG_ 3221225472 LED_L_Abbiegel_Dimmung 0;
BA_ "Fehlerwert" SG_ 3221225472 LED_R_Abbiegel_Dimmung 255;
BA_ "GenSigSendType" SG_ 3221225472 LED_R_Abbiegel_Dimmung 0;
BA_ "GenSigSendType" SG_ 2527679510 LED_Feh_LM_L_03_CRC 0;
BA_ "GenSigSendType" SG_ 2527679510 LED_Feh_LM_L_03_BZ 0;
BA_ "GenSigSendType" SG_ 2527679510 LED_L_Abbiegel_Def 0;
BA_ "GenSigSendType" SG_ 2527679510 LED_L_Abblendl_Def 0;
BA_ "GenSigSendType" SG_ 2527679510 LED_L_Allg_Elektr_Def 0;
BA_ "GenSigSendType" SG_ 2527679510 LED_L_Fernl_Def 0;
BA_ "GenSigSendType" SG_ 2527679510 LED_L_falsch_codiert 0;
BA_ "GenSigSendType" SG_ 2527679511 LED_Feh_LM_R_03_CRC 0;
BA_ "GenSigSendType" SG_ 2527679511 LED_Feh_LM_R_03_BZ 0;
BA_ "GenSigSendType" SG_ 2527679511 LED_R_Abbiegel_Def 0;
BA_ "GenSigSendType" SG_ 2527679511 LED_R_Abblendl_Def 0;
BA_ "GenSigSendType" SG_ 2527679511 LED_R_Allg_Elektr_Def 0;
BA_ "GenSigSendType" SG_ 2527679511 LED_R_Fernl_Def 0;
BA_ "GenSigSendType" SG_ 2527679511 LED_R_falsch_codiert 0;
BA_REL_ "GenSigTimeoutTime" BU_SG_REL_ AFS SG_ 2527679510 LED_L_Abbiegel_Def 2000;
BA_REL_ "GenSigTimeoutTime" BU_SG_REL_ AFS SG_ 2527679510 LED_L_Abblendl_Def 2000;
BA_REL_ "GenSigTimeoutTime" BU_SG_REL_ AFS SG_ 2527679510 LED_L_Allg_Elektr_Def 2000;
BA_REL_ "GenSigTimeoutTime" BU_SG_REL_ AFS SG_ 2527679510 LED_L_Fernl_Def 2000;
BA_REL_ "GenSigTimeoutTime" BU_SG_REL_ AFS SG_ 2527679510 LED_L_falsch_codiert 2000;
BA_REL_ "GenSigTimeoutTime" BU_SG_REL_ AFS SG_ 2527679511 LED_R_Abbiegel_Def 2000;
BA_REL_ "GenSigTimeoutTime" BU_SG_REL_ AFS SG_ 2527679511 LED_R_Abblendl_Def 2000;
BA_REL_ "GenSigTimeoutTime" BU_SG_REL_ AFS SG_ 2527679511 LED_R_Allg_Elektr_Def 2000;
BA_REL_ "GenSigTimeoutTime" BU_SG_REL_ AFS SG_ 2527679511 LED_R_Fernl_Def 2000;
BA_REL_ "GenSigTimeoutTime" BU_SG_REL_ AFS SG_ 2527679511 LED_R_falsch_codiert 2000;
VAL_ 3221225472 SOA_DimAbLicht_R 255 "Fehler" ;
VAL_ 3221225472 SOA_StGlDim_R 0 "Stellgliedtest_nicht_angefordert" 1 "Stellgliedtest_angefordert" ;
VAL_ 3221225472 SOA_StGlTest_R 0 "Stellgliedtest_nicht_angefordert" 1 "Stellgliedtest_angefordert" ;
VAL_ 3221225472 SOA_RefLauf_R 0 "Referenzlauf_nicht_angefordert" 1 "Referenzlauf_angefordert" ;
VAL_ 3221225472 SOA_FehlPos_R 0 "Fehlerfallpos_aus" 1 "Fehlerfallpos_ein" ;
VAL_ 3221225472 SOA_SollPos_R 4092 "Blockgrenze_rechts" 4093 "Blockgrenze_links" 4094 "Init" 4095 "Fehler" ;
VAL_ 3221225472 SOA_DimAbLicht_L 255 "Fehler" ;
VAL_ 3221225472 SOA_StGlDim_L 0 "Stellgliedtest_nicht_angefordert" 1 "Stellgliedtest_angefordert" ;
VAL_ 3221225472 SOA_StGlTest_L 0 "Stellgliedtest_nicht_angefordert" 1 "Stellgliedtest_angefordert" ;
VAL_ 3221225472 SOA_RefLauf_L 0 "Referenzlauf_nicht_angefordert" 1 "Referenzlauf_angefordert" ;
VAL_ 3221225472 SOA_FehlPos_L 0 "Fehlerfallpos_aus" 1 "Fehlerfallpos_ein" ;
VAL_ 3221225472 SOA_SollPos_L 4092 "Blockgrenze_rechts" 4093 "Blockgrenze_links" 4094 "Init" 4095 "Fehler" ;
VAL_ 3221225472 BM_ZV_zu 0 "inaktiv" 1 "aktiv" ;
VAL_ 3221225472 BM_ZV_auf 0 "inaktiv" 1 "aktiv" ;
VAL_ 3221225472 BM_Autobahn 0 "inaktiv" 1 "aktiv" ;
VAL_ 3221225472 LCM_ECE_SAE_Umschaltung_Anf 0 "Anforderung_ECE" 1 "Anforderung_SAE" ;
VAL_ 3221225472 LCM_Signaturlicht_Anf 0 "Signaturlicht_aus" 1 "Signaturlicht_ein" ;
VAL_ 3221225472 LCM_Animiertes_TFL_Anf 0 "Default" 1 "Keine_Animation" 2 "TFL_Einschalt_Animation" 3 "TFL_Ausschalt_Animation" 4 "Animation_3" 5 "Animation_4" 6 "Animation_5" 7 "Animation_6" ;
VAL_ 3221225472 LCM_Blinkerwischen_Anf 0 "Blinker_Wischen_aus" 1 "Blinker_Wischen_ein" ;
VAL_ 3221225472 LCM_Leistungsreduzierung_Anf 0 "Init" 1 "Leistungsreduz_Stufe_1" 2 "Leistungsreduz_Stufe_2" 3 "Leistungsreduz_Stufe_3" ;
VAL_ 3221225472 LCM_PL_R_Anf 0 "PL_aus" 1 "PL_an" ;
VAL_ 3221225472 LCM_PL_L_Anf 0 "PL_aus" 1 "PL_an" ;
VAL_ 3221225472 LCM_PO_R_Anf 0 "PO_aus" 1 "PO_an" ;
VAL_ 3221225472 LCM_PO_L_Anf 0 "PO_aus" 1 "PO_an" ;
VAL_ 3221225472 LCM_univ_1_R_Anf 0 "Ausgang_aus" 1 "Ausgang_an" ;
VAL_ 3221225472 LCM_univ_1_L_Anf 0 "Ausgang_aus" 1 "Ausgang_an" ;
VAL_ 3221225472 LCM_SM_R_Anf 0 "Sidemarker_aus" 1 "Sidemarker_an" ;
VAL_ 3221225472 LCM_SM_L_Anf 0 "Sidemarker_aus" 1 "Sidemarker_an" ;
VAL_ 3221225472 LCM_Sh_R_Anf 0 "Shutter_aus" 1 "Shutter_an" ;
VAL_ 3221225472 LCM_Sh_L_Anf 0 "Shutter_aus" 1 "Shutter_an" ;
VAL_ 3221225472 LCM_Blinkerzyklus_R 0 "Blinkzyklus_inaktiv" 1 "Blinkzyklus_aktiv" ;
VAL_ 3221225472 LCM_Blinkerzyklus_L 0 "Blinkzyklus_inaktiv" 1 "Blinkzyklus_aktiv" ;
VAL_ 3221225472 LCM_Blinker_R_Anf 0 "Blinker_aus" 1 "Blinker_an" ;
VAL_ 3221225472 LCM_Blinker_L_Anf 0 "Blinker_aus" 1 "Blinker_an" ;
VAL_ 3221225472 LCM_Abschaltung_Vbat_R_Anf 0 "default" 1 "Anfrage_LCM_Abschaltung" ;
VAL_ 3221225472 LCM_Abschaltung_Vbat_L_Anf 0 "default" 1 "Anfrage_LCM_Abschaltung" ;
VAL_ 3221225472 LCM_TFL_R_Anf 0 "TFL_aus" 1 "TFL_an" ;
VAL_ 3221225472 LCM_TFL_L_Anf 0 "TFL_aus" 1 "TFL_an" ;
VAL_ 3221225472 LED_L_Abblendl_Anf 0 "nicht_angefordert" 1 "angefordert" ;
VAL_ 3221225472 LED_L_Abblendl_Schaltart 0 "Schalten_hart" 1 "Schalten_mit_Rampe" ;
VAL_ 3221225472 LED_R_Abblendl_Anf 0 "nicht_angefordert" 1 "angefordert" ;
VAL_ 3221225472 LED_R_Abblendl_Schaltart 0 "Schalten_hart" 1 "Schalten_mit_Rampe" ;
VAL_ 3221225472 LED_L_Fernl_LH_Anf 0 "nicht_angefordert" 1 "angefordert" ;
VAL_ 3221225472 LED_L_Fernl_LH_Schaltart 0 "Schalten_hart" 1 "Schalten_mit_Rampe" ;
VAL_ 3221225472 LED_R_Fernl_LH_Anf 0 "nicht_angefordert" 1 "angefordert" ;
VAL_ 3221225472 LED_R_Fernl_LH_Schaltart 0 "Schalten_hart" 1 "Schalten_mit_Rampe" ;
VAL_ 3221225472 LED_L_Nebel_All_Anf 0 "nicht_angefordert" 1 "angefordert" ;
VAL_ 3221225472 LED_L_Nebel_All_Schaltart 0 "Schalten_hart" 1 "Schalten_mit_Rampe" ;
VAL_ 3221225472 LED_R_Nebel_All_Anf 0 "nicht_angefordert" 1 "angefordert" ;
VAL_ 3221225472 LED_R_Nebel_All_Schaltart 0 "Schalten_hart" 1 "Schalten_mit_Rampe" ;
VAL_ 3221225472 LED_Sta_Diag 0 "Init" 5 "Diagnose_VAS_Tester_laeuft" 10 "Diagnose_nicht_eingeleitet" 15 "Codierung_eingeleitet" ;
VAL_ 3221225472 LED_L_Zus_Fernl_LH_Anf 0 "nicht_angefordert" 1 "angefordert" ;
VAL_ 3221225472 LED_L_Zus_Fernl_LH_Schaltart 0 "Schalten_hart" 1 "Schalten_mit_Rampe" ;
VAL_ 3221225472 LED_R_Zus_Fernl_LH_Anf 0 "nicht_angefordert" 1 "angefordert" ;
VAL_ 3221225472 LED_R_Zus_Fernl_LH_Schaltart 0 "Schalten_hart" 1 "Schalten_mit_Rampe" ;
VAL_ 3221225472 SOL_SollPos_L 4092 "reserviert" 4093 "Blockgrenze_unten" 4094 "Init" 4095 "Fehler" ;
VAL_ 3221225472 SOL_FehlPos_L 0 "Fehlerfallpos_nicht_anfahren" 1 "Fehlerfallpos_anfahren" ;
VAL_ 3221225472 SOL_RefLauf_L 0 "Referenzlauf_nicht_angefordert" 1 "Referenzlauf_angefordert" ;
VAL_ 3221225472 SOL_StGlTest_L 0 "Stellgliedtest_nicht_angefordert" 1 "Stellgliedtest_angefordert" ;
VAL_ 3221225472 SOL_Fehlloesch_L 0 "Fehlerloeschen_nicht_angefordert" 1 "Fehlerloeschen_angefordert" ;
VAL_ 3221225472 MO_StartStopp_Motorstopp 0 "Motor_Stop_inaktiv" 1 "Motor_Stop_aktiv" ;
VAL_ 3221225472 MO_StartStopp_Wiederstart 0 "Wiederstart_inaktiv" 1 "Wiederstart_aktiv" ;
VAL_ 3221225472 SOL_Tieftemp_Flag 0 "keine_Tieftemperatur" 1 "Tieftemperatur" ;
VAL_ 3221225472 SOL_SollPos_R 4092 "reserviert" 4093 "Blockgrenze_unten" 4094 "Init" 4095 "Fehler" ;
VAL_ 3221225472 SOL_FehlPos_R 0 "Fehlerfallpos_nicht_anfahren" 1 "Fehlerfallpos_anfahren" ;
VAL_ 3221225472 SOL_RefLauf_R 0 "Referenzlauf_nicht_angefordert" 1 "Referenzlauf_angefordert" ;
VAL_ 3221225472 SOL_StGlTest_R 0 "Stellgliedtest_nicht_angefordert" 1 "Stellgliedtest_angefordert" ;
VAL_ 3221225472 SOL_Fehlloesch_R 0 "Fehlerloeschen_nicht_angefordert" 1 "Fehlerloeschen_angefordert" ;
VAL_ 3221225472 SOL_Sta_Diag 0 "Init" 5 "Diagnose_VAS_Tester_laeuft" 10 "Diagnose_nicht_eingeleitet" 15 "Codierung_eingeleitet" ;
VAL_ 3221225472 LED_L_Abbiegel_Anf 0 "nicht_angefordert" 1 "angefordert" ;
VAL_ 3221225472 LED_L_Abbiegel_Schaltart 0 "Schalten_hart" 1 "Schalten_mit_Rampe" ;
VAL_ 3221225472 LED_R_Abbiegel_Anf 0 "nicht_angefordert" 1 "angefordert" ;
VAL_ 3221225472 LED_R_Abbiegel_Schaltart 0 "Schalten_hart" 1 "Schalten_mit_Rampe" ;
VAL_ 3221225472 LED_L_Autobahnl_Anf 0 "nicht_angefordert" 1 "angefordert" ;
VAL_ 3221225472 LED_L_Autobahnl_Schaltart 0 "Schalten_hart" 1 "Schalten_mit_Rampe" ;
VAL_ 3221225472 LED_R_Autobahnl_Anf 0 "nicht_angefordert" 1 "angefordert" ;
VAL_ 3221225472 LED_R_Autobahnl_Schaltart 0 "Schalten_hart" 1 "Schalten_mit_Rampe" ;
VAL_ 3221225472 LED_L_Eco_Mode_1_Anf 0 "nicht_angefordert" 1 "angefordert" ;
VAL_ 3221225472 LED_L_Eco_Mode_1_Schaltart 0 "Schalten_hart" 1 "Schalten_mit_Rampe" ;
VAL_ 3221225472 LED_R_Eco_Mode_1_Anf 0 "nicht_angefordert" 1 "angefordert" ;
VAL_ 3221225472 LED_R_Eco_Mode_1_Schaltart 0 "Schalten_hart" 1 "Schalten_mit_Rampe" ;
VAL_ 3221225472 LED_L_Eco_Mode_2_Anf 0 "nicht_angefordert" 1 "angefordert" ;
VAL_ 3221225472 LED_L_Eco_Mode_2_Schaltart 0 "Schalten_hart" 1 "Schalten_mit_Rampe" ;
VAL_ 3221225472 LED_R_Eco_Mode_2_Anf 0 "nicht_angefordert" 1 "angefordert" ;
VAL_ 3221225472 LED_R_Eco_Mode_2_Schaltart 0 "Schalten_hart" 1 "Schalten_mit_Rampe" ;
VAL_ 3221225472 LED_L_Rennl_Anf 0 "nicht_angefordert" 1 "angefordert" ;
VAL_ 3221225472 LED_L_Rennl_Schaltart 0 "Schalten_hart" 1 "Schalten_mit_Rampe" ;
VAL_ 3221225472 LED_R_Rennl_Anf 0 "nicht_angefordert" 1 "angefordert" ;
VAL_ 3221225472 LED_R_Rennl_Schaltart 0 "Schalten_hart" 1 "Schalten_mit_Rampe" ;
VAL_ 3221225472 LED_L_Stadtl_Anf 0 "nicht_angefordert" 1 "angefordert" ;
VAL_ 3221225472 LED_L_Stadtl_Schaltart 0 "Schalten_hart" 1 "Schalten_mit_Rampe" ;
VAL_ 3221225472 LED_R_Stadtl_Anf 0 "nicht_angefordert" 1 "angefordert" ;
VAL_ 3221225472 LED_R_Stadtl_Schaltart 0 "Schalten_hart" 1 "Schalten_mit_Rampe" ;
VAL_ 3221225472 LED_L_TFL_Anf 0 "TFL_aus_PO_aus" 1 "TFL_aus_PO_an" 2 "TFL_an_PO_aus" 3 "TFL_an_PO_an" ;
VAL_ 3221225472 LED_L_TFL_Schaltart 0 "Schalten_hart" 1 "Schalten_mit_Rampe" ;
VAL_ 3221225472 LED_R_TFL_Anf 0 "TFL_aus_PO_aus" 1 "TFL_aus_PO_an" 2 "TFL_an_PO_aus" 3 "TFL_an_PO_an" ;
VAL_ 3221225472 LED_R_TFL_Schaltart 0 "Schalten_hart" 1 "Schalten_mit_Rampe" ;
VAL_ 3221225472 LED_L_Touristenl_Anf 0 "nicht_angefordert" 1 "angefordert" ;
VAL_ 3221225472 LED_L_Touristenl_Schaltart 0 "Schalten_hart" 1 "Schalten_mit_Rampe" ;
VAL_ 3221225472 LED_R_Touristenl_Anf 0 "nicht_angefordert" 1 "angefordert" ;
VAL_ 3221225472 LED_R_Touristenl_Schaltart 0 "Schalten_hart" 1 "Schalten_mit_Rampe" ;
VAL_ 3221225472 LED_ECE_SAE_Umschaltung_Anf 0 "Anforderung_ECE" 1 "Anforderung_SAE" ;
VAL_ 3221225472 LED_Tag_Nacht_Umschaltung_Anf 0 "nicht_angefordert" 1 "angefordert" ;
VAL_ 3221225472 LED_L_Abbiegel_Dimmung 255 "Fehler" ;
VAL_ 3221225472 LED_R_Abbiegel_Dimmung 255 "Fehler" ;
VAL_ 2527679510 LED_L_Abbiegel_Def 0 "Init" ;
VAL_ 2527679510 LED_L_Abblendl_Def 0 "Init" ;
VAL_ 2527679510 LED_L_Allg_Elektr_Def 0 "Init" ;
VAL_ 2527679510 LED_L_Fernl_Def 0 "Init" ;
VAL_ 2527679511 LED_R_Abbiegel_Def 0 "Init" ;
VAL_ 2527679511 LED_R_Abblendl_Def 0 "Init" ;
VAL_ 2527679511 LED_R_Allg_Elektr_Def 0 "Init" ;
VAL_ 2527679511 LED_R_Fernl_Def 0 "Init" ;
